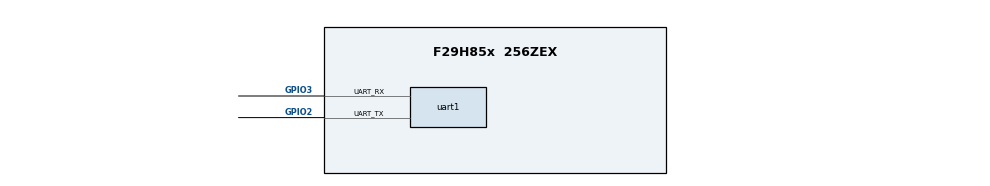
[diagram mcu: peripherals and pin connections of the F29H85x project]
/**
 * @cliArgs --device "F29H85x" --package "256ZEX" --part "F29H85x_256ZEX" --context "CPU1" --product "MCU_SDK_F29H85x@1.00.00.00"
 * @versions {"tool":"1.22.0+3877"}
 */

const divider15       = system.clockTree["PLL_REFDIV"];
divider15.divideValue = 1;

const multiplier1         = system.clockTree["PLL_IMULT"];
multiplier1.multiplyValue = 40;

const mux7       = system.clockTree["OSCCLKSRCSEL"];
mux7.inputSelect = "INTOSC2";

/**
 * Import the modules used in this configuration.
 */
const jtag  = scripting.addModule("/driverlib/jtag.js");
const uart  = scripting.addModule("/driverlib/uart.js");
const uart1 = uart.addInstance();

/**
 * Write custom configuration values to the imported modules.
 */
uart1.$name                   = "myUART0";
uart1.loopback                = true;
uart1.baud                    = 9600;
uart1.uart.$assign            = "UARTA";
uart1.uart.uart_txPin.$assign = "GPIO2";
uart1.uart.uart_rxPin.$assign = "GPIO3";
uart1.periphClock.$name       = "driverlib_perClock0";
uart1.periphConfig.$name      = "driverlib_perConfig0";
